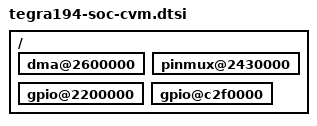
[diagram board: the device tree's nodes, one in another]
/*
 * tegra194-soc-cvm.dtsi: CVM based platform common SoC specific DTSI file
 *			  with required node enabled.
 *
 * Copyright (c) 2017, NVIDIA CORPORATION.  All rights reserved.
 *
 * This program is free software; you can redistribute it and/or modify
 * it under the terms of the GNU General Public License as published by
 * the Free Software Foundation; version 2 of the License.
 *
 * This program is distributed in the hope that it will be useful, but WITHOUT
 * ANY WARRANTY; without even the implied warranty of MERCHANTABILITY or
 * FITNESS FOR A PARTICULAR PURPOSE.  See the GNU General Public License for
 * more details.
 */

#include <tegra194-soc/tegra194-soc-base.dtsi>
#include <tegra194-soc/tegra194-cpus.dtsi>
#include <tegra194-soc/mods-simple-bus.dtsi>
#include <tegra194-soc/tegra194-soc-prod.dtsi>

/ {
	dma@2600000 {
		status = "okay";
	};

	pinmux@2430000 {
		status = "okay";
	};

	gpio@2200000 {
		status = "okay";
	};

	gpio@c2f0000 {
		status = "okay";
	};
};
